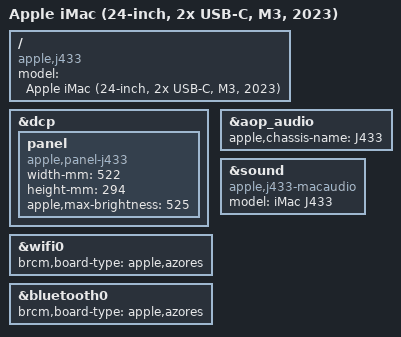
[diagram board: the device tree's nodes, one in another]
// SPDX-License-Identifier: GPL-2.0+ OR MIT
/*
 * Apple iMac (24-inch, 2x USB-C, M3, 2023)
 *
 * target-type: J433
 *
 * Copyright The Asahi Linux Contributors
 */

/dts-v1/;

#include "t8122.dtsi"
#include "t8122-j433-j434.dtsi"

/ {
	compatible = "apple,j433", "apple,t8122", "apple,arm-platform";
	model = "Apple iMac (24-inch, 2x USB-C, M3, 2023)";
};

&dcp {
	panel: panel {
		compatible = "apple,panel-j433", "apple,panel";
		width-mm = <522>;
		height-mm = <294>;
		apple,max-brightness = <525>;
	};
};

&wifi0 {
	brcm,board-type = "apple,azores";
};

&bluetooth0 {
	brcm,board-type = "apple,azores";
};

&aop_audio {
	apple,chassis-name = "J433";
};

&sound {
	compatible = "apple,j433-macaudio", "apple,macaudio";
	model = "iMac J433";
};
